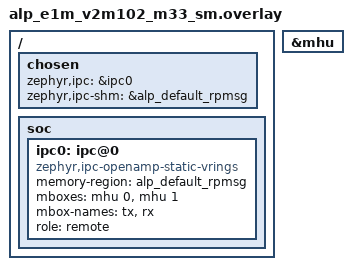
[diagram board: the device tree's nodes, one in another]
/*
 * Copyright 2026 ALP Lab AB
 * SPDX-License-Identifier: Apache-2.0
 *
 * Devicetree overlay for the M33 system-manager slice of an
 * E1M-V2M102 (V2N + DEEPX DX-M1, larger memory) heterogeneous
 * project.  Identical to V2M101 wiring at the M33 level; the SoM
 * delta is on-module memory capacity only.
 */

#include "../../build/generated/dts-reservations.dtsi"

/ {
    chosen {
        zephyr,ipc     = &ipc0;
        zephyr,ipc-shm = &alp_default_rpmsg;
    };

    soc {
        ipc0: ipc@0 {
            compatible = "zephyr,ipc-openamp-static-vrings";
            memory-region = <&alp_default_rpmsg>;
            mboxes = <&mhu 0>, <&mhu 1>;
            mbox-names = "tx", "rx";
            role = "remote";
            status = "okay";
        };
    };
};

&mhu {
    status = "okay";
};
